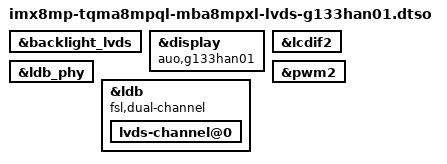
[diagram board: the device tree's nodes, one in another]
// SPDX-License-Identifier: (GPL-2.0-or-later OR MIT)
/*
 * Copyright (c) 2023-2026 TQ-Systems GmbH <linux@ew.tq-group.com>,
 * D-82229 Seefeld, Germany.
 * Author: Alexander Stein
 */

/dts-v1/;
/plugin/;

#include <dt-bindings/clock/imx8mp-clock.h>

&backlight_lvds {
	status = "okay";
};

&display {
	compatible = "auo,g133han01";
	status = "okay";
};

&lcdif2 {
	status = "okay";
};

&ldb_phy {
	status = "okay";
};

&ldb {
	fsl,dual-channel;
	status = "okay";

	lvds-channel@0 {
		status = "okay";
	};
};

&pwm2 {
	status = "okay";
};
